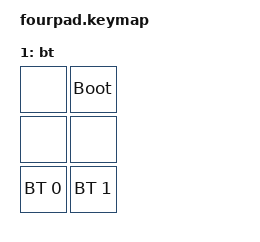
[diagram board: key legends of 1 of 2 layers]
#include <behaviors.dtsi>
#include <dt-bindings/zmk/keys.h>
#include <dt-bindings/zmk/bt.h>

/ {
        keymap {
                compatible = "zmk,keymap";
                label = "fourpad";
		
                default_layer {
                label = "Default";
                	bindings = <
                    &kp KP_N7 &kp KP_N8
                    &kp KP_N4 &kp KP_N5
                        >;
                };

                bt_layer {
                label = "bt";
                	bindings = <
                    &none &bootloader
                    &none &none
                    &bt BT_SEL 0 &bt BT_SEL 1
                        >;
                };

        };
};
